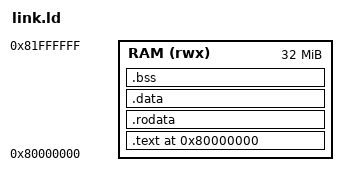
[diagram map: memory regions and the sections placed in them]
OUTPUT_ARCH(riscv)
ENTRY(_start)

MEMORY {
    RAM (rwx) : ORIGIN = 0x80000000, LENGTH = 32M
}

SECTIONS {
    . = 0x80000000;

    .text : {
        *(.text.start)
        *(.text*)
    } > RAM

    .rodata : ALIGN(4) {
        *(.rodata*)
    } > RAM

    .data : ALIGN(4) {
        *(.data*)
    } > RAM

    .bss : ALIGN(4) {
        _bss_start = .;
        *(.bss*)
        *(COMMON)
        _bss_end = .;
    } > RAM

    /* Stack at the very top of RAM (grows downward) */
    _stack_top = ORIGIN(RAM) + LENGTH(RAM);
}
